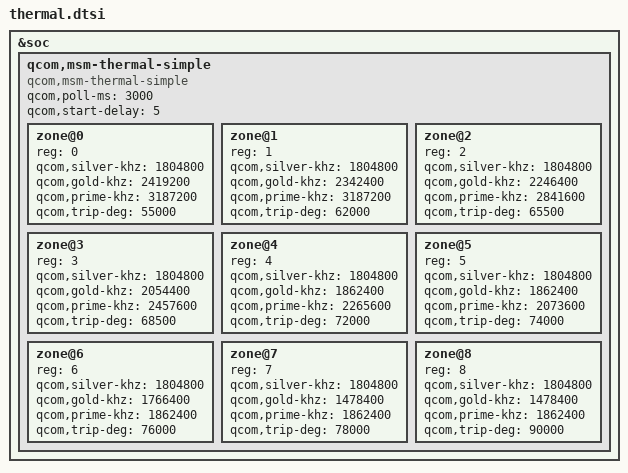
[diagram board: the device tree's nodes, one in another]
&soc {
	qcom,msm-thermal-simple {
		compatible = "qcom,msm-thermal-simple";
		qcom,poll-ms = <3000>;
		qcom,start-delay = <5>;

		zone@0 {
			reg = <0>;
			qcom,silver-khz = <1804800>;
			qcom,gold-khz = <2419200>;
			qcom,prime-khz = <3187200>;
			qcom,trip-deg = <55000>;
		};

		zone@1 {
			reg = <1>;
			qcom,silver-khz = <1804800>;
			qcom,gold-khz = <2342400>;
			qcom,prime-khz = <3187200>;
			qcom,trip-deg = <62000>;
		};

		zone@2 {
			reg = <2>;
			qcom,silver-khz = <1804800>;
			qcom,gold-khz = <2246400>;
			qcom,prime-khz = <2841600>;
			qcom,trip-deg = <65500>;
		};

		zone@3 {
			reg = <3>;
			qcom,silver-khz = <1804800>;
			qcom,gold-khz = <2054400>;
			qcom,prime-khz = <2457600>;
			qcom,trip-deg = <68500>;
		};

		zone@4 {
			reg = <4>;
			qcom,silver-khz = <1804800>;
			qcom,gold-khz = <1862400>;
			qcom,prime-khz = <2265600>;
			qcom,trip-deg = <72000>;
		};

		zone@5 {
			reg = <5>;
			qcom,silver-khz = <1804800>;
			qcom,gold-khz = <1862400>;
			qcom,prime-khz = <2073600>;
			qcom,trip-deg = <74000>;
		};

		zone@6 {
			reg = <6>;
			qcom,silver-khz = <1804800>;
			qcom,gold-khz = <1766400>;
			qcom,prime-khz = <1862400>;
			qcom,trip-deg = <76000>;
		};

		zone@7 {
			reg = <7>;
			qcom,silver-khz = <1804800>;
			qcom,gold-khz = <1478400>;
			qcom,prime-khz = <1862400>;
			qcom,trip-deg = <78000>;
		};


		zone@8 {
			reg = <8>;
			qcom,silver-khz = <1804800>;
			qcom,gold-khz = <1478400>;
			qcom,prime-khz = <1862400>;
			qcom,trip-deg = <90000>;
		};
	};
};
